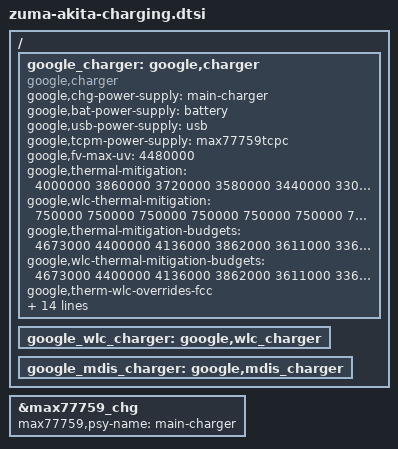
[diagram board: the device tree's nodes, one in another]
// SPDX-License-Identifier: GPL-2.0-only
/*
 * Battery device tree entries specific to akita
 *
 * Copyright 2022 Google LLC
 *
 */

/ {
	fragment@charging {
		target-path = "/";
		__overlay__ {

			google_charger: google,charger {
				status = "okay";
				compatible = "google,charger";
				#cooling-cells = <2>;

				google,chg-power-supply = "main-charger"; /* max77759-charger */
				google,bat-power-supply = "battery";
				google,usb-power-supply = "usb";
				google,tcpm-power-supply = <&max77759tcpc>;

				google,fv-max-uv = <4480000>;

				google,thermal-mitigation =
				<4000000 3860000 3720000 3580000 3440000 3300000 3160000 3020000 2880000
				 2740000 2600000 2460000 2320000 2180000 2040000 1900000 1760000 1620000
				 1480000 1340000 1200000 1060000  920000  780000  640000  500000>;

				google,wlc-thermal-mitigation =
				<750000 750000 750000 750000 750000 750000 750000 750000 750000
				 750000 750000 750000 700000 650000 600000 550000 500000 450000
				 400000 350000 300000 250000 250000 250000 250000 250000>;

				// thermal budgets
				google,thermal-mitigation-budgets =
				<4673000 4400000 4136000 3862000 3611000 3369000 3135000 2861000 2636000
				 2421000 2220000 2028000 1841000 1665000 1497000 1350000 1209000 1075000
				  947000  844000  744000  646000  582000  512000  435000  353000>;
				google,wlc-thermal-mitigation-budgets =
				<4673000 4400000 4136000 3862000 3611000 3369000 3135000 2861000 2636000
				 2421000 2220000 2028000 1841000 1665000 1497000 1350000 1209000 1075000
				  947000  844000  744000  646000  582000  512000  435000  353000>;
				google,therm-wlc-overrides-fcc;
				google,thermal-stats-lvl-map = <0 2 5 8 11>;

				google,wlc-thermal-dc-fan-alarm = <2>;

				/* b/170700459 thresholds, updated in b/191070950 */
				google,bd-resume-abs-temp = <280>;
				google,bd-resume-soc = <50>;
				google,bd-resume-time = <14400>;  /* 4 hours */
				google,bd-resume-temp = <290>;
				google,bd-trigger-time = <21600>; /* 6 hours */
				google,bd-trigger-temp = <350>;
				google,bd-trigger-voltage = <4270000>;
				google,bd-recharge-voltage = <4250000>;
				google,bd-drainto-soc = <80>;
				google,bd-recharge-soc = <79>;
				/* Enable TEMP-DEFEND */
				google,bd-temp-enable;

				google,chg-termination-5v;
			};

			google_wlc_charger: google,wlc_charger {
				#cooling-cells = <2>;
			};

			google_mdis_charger: google,mdis_charger {
				#cooling-cells = <2>;
			};

		};
	};
};

&max77759_chg {
	max77759,psy-name = "main-charger";
};
